# colorlight register map
Vendor: litex
Litex SoC 2026-09-10 11:56:52
Registers are 32-bit, read-write, reset 0x0 unless marked. A register's access mark holds for its fields unless they carry their own. Offsets are from the block's base; lines under a group give offsets from that group; [hi:lo] are bit positions; {n}, {i} and the like mark numbered series; 'fields as' and 'values as' point back to an identical list; <NAME> marks a mode.

## Memory map
0x80000000 ETHMEM size 0x4000
0xF0000000 SPIFLASH_MMAP size 0x14
0xF0000800 SPIFLASH_PHY size 0x4
0xF0001000 DMATEST size 0x18
0xF0001800 PIXDMA size 0x48
0xF0002000 CTRL size 0xC
0xF0002800 ETHMAC size 0x84
0xF0003000 ETHPHY size 0x10
0xF0003800 HUB75_PALETTE size 0x4
0xF0004000 HUB75 size 0x48
0xF0004800 IDENTIFIER_MEM size 0x4
0xF0005000 SDRAM size 0x1C
0xF0005800 TIMER0 size 0x20
0xF0006000 UART size 0x20

## Interrupts
0 uart (UART)
1 timer0 (TIMER0)
2 ethmac (ETHMAC)

## Further device data
memoryRegions:
  ROM baseAddress=0x00000000 size=0x00010000
  SRAM baseAddress=0x10000000 size=0x00002000
  SPIFLASH baseAddress=0x80400000 size=0x00400000
  MAIN_RAM baseAddress=0x40000000 size=0x00400000
  MAIN_RAM_UNCACHED baseAddress=0x90000000 size=0x00400000
  ETHMAC baseAddress=0x80000000 size=0x00005000
  ETHMAC_RX baseAddress=0x80000000 size=0x00004000
  ETHMAC_TX baseAddress=0x80004000 size=0x00001000
  CSR baseAddress=0xF0000000 size=0x00010000
constants:
  CONFIG_PLATFORM_NAME value=colorlight_5a_75e
  CONFIG_CLOCK_FREQUENCY value=40000000
  CONFIG_CPU_HAS_INTERRUPT value=None
  CONFIG_CPU_RESET_ADDR value=0
  CONFIG_CPU_HAS_ICACHE value=None
  CONFIG_CPU_TYPE_VEXRISCV value=None
  CONFIG_CPU_VARIANT_LITE value=None
  CONFIG_CPU_FAMILY value=riscv
  CONFIG_CPU_NAME value=vexriscv
  CONFIG_CPU_HUMAN_NAME value=VexRiscv_Lite
  CONFIG_CPU_NOP value=nop
  CONFIG_IDENTIFIER value=LiteX SoC on Colorlight 5A-75E 2026-09-10 11:54:39
  FLASH_BOOT_ADDRESS value=2152726528
  SPIFLASH_PAGE_SIZE value=256
  CONFIG_L2_SIZE value=8192
  ETH_PHY_NO_RESET value=None
  LOCALIP1 value=10
  LOCALIP2 value=11
  LOCALIP3 value=6
  LOCALIP4 value=250
  REMOTEIP1 value=10
  REMOTEIP2 value=11
  REMOTEIP3 value=6
  REMOTEIP4 value=65
  TFTP_SERVER_PORT value=6969
  SDRAM_TEST_DISABLE value=None
  CONFIG_CSR_DATA_WIDTH value=32
  CONFIG_CSR_ALIGNMENT value=32
  CONFIG_CSR_ORDERING_BIG value=None
  CONFIG_BUS_STANDARD value=wishbone
  CONFIG_BUS_DATA_WIDTH value=32
  CONFIG_BUS_ADDRESS_WIDTH value=32
  CONFIG_BUS_BURSTING value=0
  ETHMAC_RX_SLOTS value=8
  ETHMAC_TX_SLOTS value=2
  ETHMAC_SLOT_SIZE value=2048
  CONFIG_CPU_INTERRUPTS value=3
  ETHMAC_INTERRUPT value=2
  TIMER0_INTERRUPT value=1
  UART_INTERRUPT value=0

## SPIFLASH_MMAP
Base 0xF0000000
0x00 MMAP_DUMMY_BITS
  [7:0] mmap_dummy_bits
0x04 MASTER_CS
  [0] master_cs
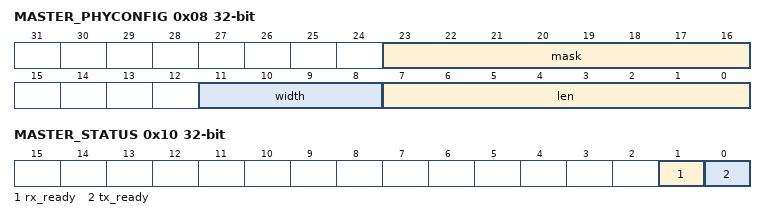
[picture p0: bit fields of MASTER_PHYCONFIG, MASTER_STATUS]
0x08 MASTER_PHYCONFIG — SPI PHY settings.
  [23:16] mask — SPI DQ output enable mask (set bits to ``1`` to enable output drivers on DQ lines).
  [11:8] width — SPI Xfer width (1/2/4/8).
  [7:0] len — SPI Xfer length (in bits).
0x0C MASTER_RXTX
0x10 MASTER_STATUS
  [1] rx_ready — RX FIFO is not empty.
  [0] tx_ready — TX FIFO is not full.

## SPIFLASH_PHY
Base 0xF0000800
0x00 CLK_DIVISOR reset 0x9
  [7:0] clk_divisor

## DMATEST
Base 0xF0001000
0x00 BASE — First word address of the burst
  [23:0] base
0x04 LENGTH — Words to write in the burst
  [23:0] length
0x08 CTRL
  [0] start — Write 1 to arm a burst (self-clearing pulse)
0x0C STATUS
  [0] busy — Burst in progress
0x10 CYCLES — Sys-clk cycles taken by the last burst
0x14 WRITTEN — Words written by the last burst

## PIXDMA
Base 0xF0001800
0x00 BASE — Derived framebuffer write address (read-only)
  [23:0] base
0x04 LIMIT — Pixels in the image; writes past this are dropped
  [23:0] limit
0x08 CTRL
  [0] enable — Enable hardware pixel writes
0x0C PIXELS — Pixels written
0x10 CHUNKS — Chunks accepted
0x14 BAD_MAGIC — Payloads rejected on magic
0x18 LAST_CHUNK — Most recent chunk_index
  [7:0] last_chunk
0x1C STATUS
  [0] busy — A payload is being written
0x20 STALLS — Payloads abandoned after a DRAM stall
{0x24+4i} ARRIVAL{i} (i=0..7) — Chunk arrival bitmap word {i}
0x44 FRAME_ID — frame_id the arrival bitmap describes
  [15:0] frame_id
